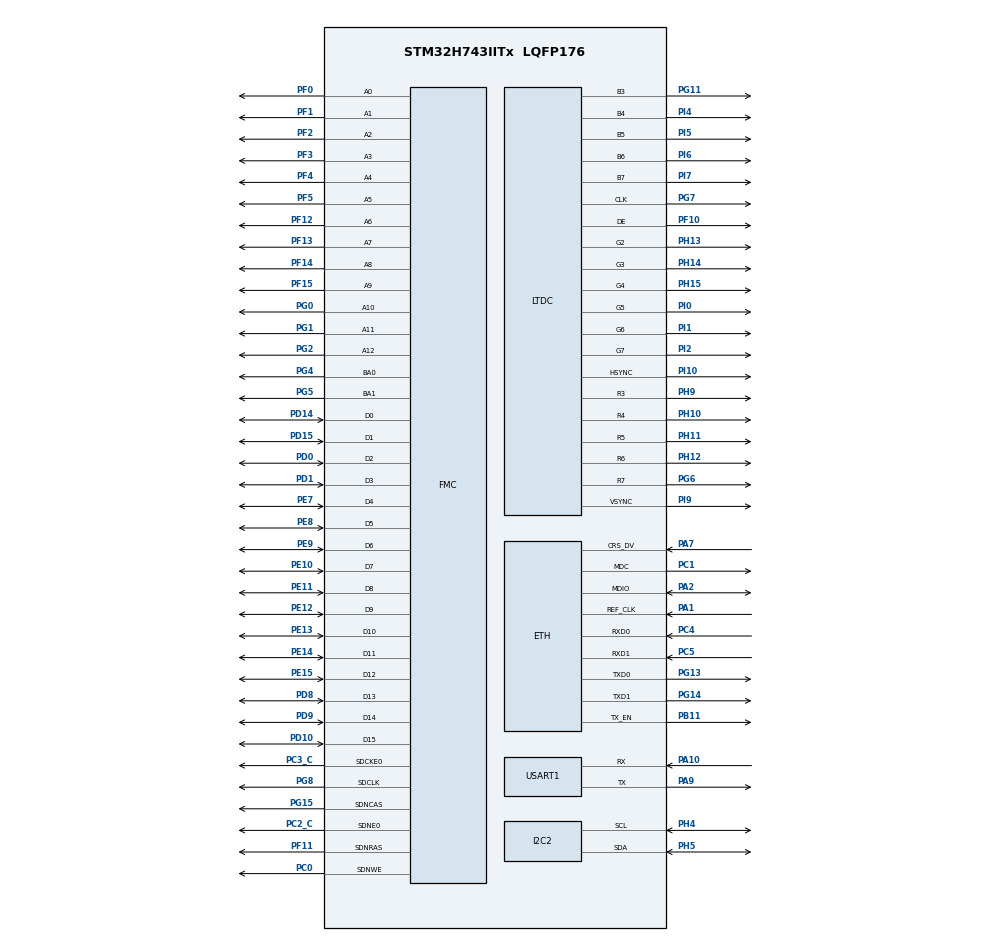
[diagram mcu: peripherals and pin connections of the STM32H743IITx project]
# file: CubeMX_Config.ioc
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CORTEX_M7.AccessPermission-Cortex_Memory_Protection_Unit_Region2_Settings=MPU_REGION_FULL_ACCESS
CORTEX_M7.AccessPermission-Cortex_Memory_Protection_Unit_Region3_Settings=MPU_REGION_FULL_ACCESS
CORTEX_M7.BaseAddress-Cortex_Memory_Protection_Unit_Region2_Settings=0x30040000
CORTEX_M7.BaseAddress-Cortex_Memory_Protection_Unit_Region3_Settings=0x30044000
CORTEX_M7.CPU_DCache=Enabled
CORTEX_M7.CPU_ICache=Enabled
CORTEX_M7.Enable-Cortex_Memory_Protection_Unit_Region2_Settings=MPU_REGION_ENABLE
CORTEX_M7.Enable-Cortex_Memory_Protection_Unit_Region3_Settings=MPU_REGION_ENABLE
CORTEX_M7.IsBufferable-Cortex_Memory_Protection_Unit_Region2_Settings=MPU_ACCESS_BUFFERABLE
CORTEX_M7.IsCacheable-Cortex_Memory_Protection_Unit_Region3_Settings=MPU_ACCESS_CACHEABLE
CORTEX_M7.MPU_Control=MPU_PRIVILEGED_DEFAULT
CORTEX_M7.Size-Cortex_Memory_Protection_Unit_Region2_Settings=MPU_REGION_SIZE_256B
CORTEX_M7.Size-Cortex_Memory_Protection_Unit_Region3_Settings=MPU_REGION_SIZE_16KB
DMA2D.ColorMode=DMA2D_OUTPUT_RGB565
DMA2D.Mode=DMA2D_R2M
ETH.MediaInterface=HAL_ETH_RMII_MODE
FMC.CASLatency1=FMC_SDRAM_CAS_LATENCY_2
FMC.ColumnBitsNumber1=FMC_SDRAM_COLUMN_BITS_NUM_9
FMC.ExitSelfRefreshDelay1=8
FMC.LoadToActiveDelay1=2
FMC.RCDDelay1=2
FMC.RPDelay1=2
FMC.ReadBurst1=FMC_SDRAM_RBURST_ENABLE
FMC.ReadPipeDelay1=FMC_SDRAM_RPIPE_DELAY_1
FMC.RowCycleDelay1=6
FMC.SDClockPeriod1=FMC_SDRAM_CLOCK_PERIOD_2
FMC.SelfRefreshTime1=6
FMC.WriteRecoveryTime1=4
I2C2.Timing=0x10C0ECFF
Mcu.Family=STM32H7
Mcu.Name=STM32H743IITx
Mcu.Package=LQFP176
NVIC.ETH_IRQn=true\:0\:0\:false\:false\:true\:true\:true
NVIC.PriorityGroup=NVIC_PRIORITYGROUP_4
NVIC.USART1_IRQn=true\:0\:0\:false\:false\:true\:true\:true
PA1.GPIO_Speed=GPIO_SPEED_FREQ_VERY_HIGH
PA1.Mode=RMII
PA1.Signal=ETH_REF_CLK
PA10.GPIO_Speed=GPIO_SPEED_FREQ_HIGH
PA10.Mode=Asynchronous
PA10.Signal=USART1_RX
PA13\ (JTMS/SWDIO).Mode=Serial_Wire
PA13\ (JTMS/SWDIO).Signal=SYS_JTMS-SWDIO
PA14\ (JTCK/SWCLK).Mode=Serial_Wire
PA14\ (JTCK/SWCLK).Signal=SYS_JTCK-SWCLK
PA2.GPIO_Speed=GPIO_SPEED_FREQ_VERY_HIGH
PA2.Mode=RMII
PA2.Signal=ETH_MDIO
PA7.GPIO_Speed=GPIO_SPEED_FREQ_VERY_HIGH
PA7.Mode=RMII
PA7.Signal=ETH_CRS_DV
PA9.GPIO_Speed=GPIO_SPEED_FREQ_HIGH
PA9.Mode=Asynchronous
PA9.Signal=USART1_TX
PB11.GPIO_Speed=GPIO_SPEED_FREQ_VERY_HIGH
PB11.Mode=RMII
PB11.Signal=ETH_TX_EN
PC0.Signal=FMC_SDNWE
PC1.Mode=RMII
PC1.Signal=ETH_MDC
PC2_C.Mode=SdramChipSelect1_1
PC2_C.Signal=FMC_SDNE0
PC3_C.Mode=SdramChipSelect1_1
PC3_C.Signal=FMC_SDCKE0
PC4.GPIO_Speed=GPIO_SPEED_FREQ_VERY_HIGH
PC4.Mode=RMII
PC4.Signal=ETH_RXD0
PC5.GPIO_Speed=GPIO_SPEED_FREQ_VERY_HIGH
PC5.Mode=RMII
PC5.Signal=ETH_RXD1
PD0.Signal=FMC_D2_DA2
PD1.Signal=FMC_D3_DA3
PD10.Signal=FMC_D15_DA15
PD14.Signal=FMC_D0_DA0
PD15.Signal=FMC_D1_DA1
PD8.Signal=FMC_D13_DA13
PD9.Signal=FMC_D14_DA14
PE0.Signal=FMC_NBL0
PE1.Signal=FMC_NBL1
PE10.Signal=FMC_D7_DA7
PE11.Signal=FMC_D8_DA8
PE12.Signal=FMC_D9_DA9
PE13.Signal=FMC_D10_DA10
PE14.Signal=FMC_D11_DA11
PE15.Signal=FMC_D12_DA12
PE7.Signal=FMC_D4_DA4
PE8.Signal=FMC_D5_DA5
PE9.Signal=FMC_D6_DA6
PF0.Signal=FMC_A0
PF1.Signal=FMC_A1
PF10.Mode=RGB565
PF10.Signal=LTDC_DE
PF11.Signal=FMC_SDNRAS
PF12.Signal=FMC_A6
PF13.Signal=FMC_A7
PF14.Signal=FMC_A8
PF15.Signal=FMC_A9
PF2.Signal=FMC_A2
PF3.Signal=FMC_A3
PF4.Signal=FMC_A4
PF5.Signal=FMC_A5
PG0.Signal=FMC_A10
PG1.Signal=FMC_A11
PG11.Mode=RGB565
PG11.Signal=LTDC_B3
PG13.GPIO_Speed=GPIO_SPEED_FREQ_VERY_HIGH
PG13.Mode=RMII
PG13.Signal=ETH_TXD0
PG14.GPIO_Speed=GPIO_SPEED_FREQ_VERY_HIGH
PG14.Mode=RMII
PG14.Signal=ETH_TXD1
PG15.Signal=FMC_SDNCAS
PG2.Signal=FMC_A12
PG4.Signal=FMC_A14_BA0
PG5.Signal=FMC_A15_BA1
PG6.Mode=RGB565
PG6.Signal=LTDC_R7
PG7.Mode=RGB565
PG7.Signal=LTDC_CLK
PG8.Signal=FMC_SDCLK
PH0-OSC_IN\ (PH0).Mode=HSE-External-Oscillator
PH0-OSC_IN\ (PH0).Signal=RCC_OSC_IN
PH1-OSC_OUT\ (PH1).Mode=HSE-External-Oscillator
PH1-OSC_OUT\ (PH1).Signal=RCC_OSC_OUT
PH10.Mode=RGB565
PH10.Signal=LTDC_R4
PH11.Mode=RGB565
PH11.Signal=LTDC_R5
PH12.Mode=RGB565
PH12.Signal=LTDC_R6
PH13.Mode=RGB565
PH13.Signal=LTDC_G2
PH14.Mode=RGB565
PH14.Signal=LTDC_G3
PH15.Mode=RGB565
PH15.Signal=LTDC_G4
PH4.GPIO_Speed=GPIO_SPEED_FREQ_HIGH
PH4.Mode=I2C
PH4.Signal=I2C2_SCL
PH5.GPIO_Speed=GPIO_SPEED_FREQ_HIGH
PH5.Mode=I2C
PH5.Signal=I2C2_SDA
PH9.Mode=RGB565
PH9.Signal=LTDC_R3
PI0.Mode=RGB565
PI0.Signal=LTDC_G5
PI1.Mode=RGB565
PI1.Signal=LTDC_G6
PI10.Mode=RGB565
PI10.Signal=LTDC_HSYNC
PI2.Mode=RGB565
PI2.Signal=LTDC_G7
PI4.Mode=RGB565
PI4.Signal=LTDC_B4
PI5.Mode=RGB565
PI5.Signal=LTDC_B5
PI6.Mode=RGB565
PI6.Signal=LTDC_B6
PI7.Mode=RGB565
PI7.Signal=LTDC_B7
PI9.Mode=RGB565
PI9.Signal=LTDC_VSYNC
ProjectManager.HeapSize=0x200
ProjectManager.StackSize=0x400
ProjectManager.TargetToolchain=MDK-ARM V5
RCC.ADCFreq_Value=50390625
RCC.APB1Freq_Value=100000000
RCC.APB2Freq_Value=100000000
RCC.APB3Freq_Value=100000000
RCC.APB4Freq_Value=100000000
RCC.CortexFreq_Value=400000000
RCC.D1PPRE=RCC_APB3_DIV2
RCC.D2PPRE1=RCC_APB1_DIV2
RCC.D2PPRE2=RCC_APB2_DIV2
RCC.D3PPRE=RCC_APB4_DIV2
RCC.DIVM1=5
RCC.DIVM3=5
RCC.DIVN1=160
RCC.DIVN3=160
RCC.DIVR3=88
RCC.HCLKFreq_Value=200000000
RCC.HPRE=RCC_HCLK_DIV2
RCC.HSE_VALUE=25000000
RCC.PLLSourceVirtual=RCC_PLLSOURCE_HSE
RCC.SYSCLKFreq_VALUE=400000000
RCC.SYSCLKSource=RCC_SYSCLKSOURCE_PLLCLK
RCC.USBFreq_Value=400000000
SH.FMC_A0.0=FMC_A0,13b-sda1
SH.FMC_A1.0=FMC_A1,13b-sda1
SH.FMC_A10.0=FMC_A10,13b-sda1
SH.FMC_A11.0=FMC_A11,13b-sda1
SH.FMC_A12.0=FMC_A12,13b-sda1
SH.FMC_A14_BA0.0=FMC_BA0,FourSdramBanks1
SH.FMC_A15_BA1.0=FMC_BA1,FourSdramBanks1
SH.FMC_A2.0=FMC_A2,13b-sda1
SH.FMC_A3.0=FMC_A3,13b-sda1
SH.FMC_A4.0=FMC_A4,13b-sda1
SH.FMC_A5.0=FMC_A5,13b-sda1
SH.FMC_A6.0=FMC_A6,13b-sda1
SH.FMC_A7.0=FMC_A7,13b-sda1
SH.FMC_A8.0=FMC_A8,13b-sda1
SH.FMC_A9.0=FMC_A9,13b-sda1
SH.FMC_D0_DA0.0=FMC_D0,sd-16b-d1
SH.FMC_D10_DA10.0=FMC_D10,sd-16b-d1
SH.FMC_D11_DA11.0=FMC_D11,sd-16b-d1
SH.FMC_D12_DA12.0=FMC_D12,sd-16b-d1
SH.FMC_D13_DA13.0=FMC_D13,sd-16b-d1
SH.FMC_D14_DA14.0=FMC_D14,sd-16b-d1
SH.FMC_D15_DA15.0=FMC_D15,sd-16b-d1
SH.FMC_D1_DA1.0=FMC_D1,sd-16b-d1
SH.FMC_D2_DA2.0=FMC_D2,sd-16b-d1
SH.FMC_D3_DA3.0=FMC_D3,sd-16b-d1
SH.FMC_D4_DA4.0=FMC_D4,sd-16b-d1
SH.FMC_D5_DA5.0=FMC_D5,sd-16b-d1
SH.FMC_D6_DA6.0=FMC_D6,sd-16b-d1
SH.FMC_D7_DA7.0=FMC_D7,sd-16b-d1
SH.FMC_D8_DA8.0=FMC_D8,sd-16b-d1
SH.FMC_D9_DA9.0=FMC_D9,sd-16b-d1
SH.FMC_NBL0.0=FMC_NBL0
SH.FMC_NBL1.0=FMC_NBL1
SH.FMC_SDCLK.0=FMC_SDCLK,13b-sda1
SH.FMC_SDNCAS.0=FMC_SDNCAS,13b-sda1
SH.FMC_SDNRAS.0=FMC_SDNRAS,13b-sda1
SH.FMC_SDNWE.0=FMC_SDNWE,13b-sda1
USART1.VirtualMode-Asynchronous=VM_ASYNC
VP_DMA2D_VS_DMA2D.Mode=DMA2D_Activate
board=custom

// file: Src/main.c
/* USER CODE BEGIN Header */
/**
  ******************************************************************************
  * @file           : main.c
  * @brief          : Main program body
  ******************************************************************************
  ** This notice applies to any and all portions of this file
  * that are not between comment pairs USER CODE BEGIN and
  * USER CODE END. Other portions of this file, whether
  * inserted by the user or by software development tools
  * are owned by their respective copyright owners.
  *
  * COPYRIGHT(c) 2019 STMicroelectronics
  *
  * Redistribution and use in source and binary forms, with or without modification,
  * are permitted provided that the following conditions are met:
  *   1. Redistributions of source code must retain the above copyright notice,
  *      this list of conditions and the following disclaimer.
  *   2. Redistributions in binary form must reproduce the above copyright notice,
  *      this list of conditions and the following disclaimer in the documentation
  *      and/or other materials provided with the distribution.
  *   3. Neither the name of STMicroelectronics nor the names of its contributors
  *      may be used to endorse or promote products derived from this software
  *      without specific prior written permission.
  *
  * THIS SOFTWARE IS PROVIDED BY THE COPYRIGHT HOLDERS AND CONTRIBUTORS "AS IS"
  * AND ANY EXPRESS OR IMPLIED WARRANTIES, INCLUDING, BUT NOT LIMITED TO, THE
  * IMPLIED WARRANTIES OF MERCHANTABILITY AND FITNESS FOR A PARTICULAR PURPOSE ARE
  * DISCLAIMED. IN NO EVENT SHALL THE COPYRIGHT HOLDER OR CONTRIBUTORS BE LIABLE
  * FOR ANY DIRECT, INDIRECT, INCIDENTAL, SPECIAL, EXEMPLARY, OR CONSEQUENTIAL
  * DAMAGES (INCLUDING, BUT NOT LIMITED TO, PROCUREMENT OF SUBSTITUTE GOODS OR
  * SERVICES; LOSS OF USE, DATA, OR PROFITS; OR BUSINESS INTERRUPTION) HOWEVER
  * CAUSED AND ON ANY THEORY OF LIABILITY, WHETHER IN CONTRACT, STRICT LIABILITY,
  * OR TORT (INCLUDING NEGLIGENCE OR OTHERWISE) ARISING IN ANY WAY OUT OF THE USE
  * OF THIS SOFTWARE, EVEN IF ADVISED OF THE POSSIBILITY OF SUCH DAMAGE.
  *
  ******************************************************************************
  */
/* USER CODE END Header */

#include "main.h"

/* USER CODE BEGIN Includes */
#include "pcf8574.h"
#include "stdio.h"
/* USER CODE END Includes */

DMA2D_HandleTypeDef hdma2d;

ETH_HandleTypeDef heth;

I2C_HandleTypeDef hi2c2;

LTDC_HandleTypeDef hltdc;

UART_HandleTypeDef huart1;

SDRAM_HandleTypeDef hsdram1;

void SystemClock_Config(void);
static void MPU_Config(void);
static void MX_GPIO_Init(void);
static void MX_USART1_UART_Init(void);
static void MX_FMC_Init(void);
static void MX_DMA2D_Init(void);
static void MX_LTDC_Init(void);
static void MX_I2C2_Init(void);
static void MX_ETH_Init(void);

/* USER CODE BEGIN 0 */
int fputc(int ch, FILE *f)
{
    HAL_UART_Transmit(&huart1, (uint8_t *)&ch, 1, 1000);
    return ch;
}
/* USER CODE END 0 */

int main(void)
{

  /* MPU Configuration--------------------------------------------------------*/
  MPU_Config();

  /* Enable I-Cache---------------------------------------------------------*/
  SCB_EnableICache();

  /* Enable D-Cache---------------------------------------------------------*/
  SCB_EnableDCache();

  /* MCU Configuration--------------------------------------------------------*/

  /* Reset of all peripherals, Initializes the Flash interface and the Systick. */
  HAL_Init();

  /* USER CODE BEGIN Init */
    __HAL_RCC_D2SRAM3_CLK_ENABLE();
  /* USER CODE END Init */

  /* Configure the system clock */
  SystemClock_Config();

  /* Initialize all configured peripherals */
  MX_GPIO_Init();
  MX_USART1_UART_Init();
  MX_FMC_Init();
  MX_DMA2D_Init();
  MX_LTDC_Init();
  MX_I2C2_Init();
  MX_ETH_Init();
  /* USER CODE BEGIN 2 */
  MX_LWIP_Init();
    printf("开始\r\n");
  /* USER CODE END 2 */

  /* Infinite loop */
  while (1)
  {

    /* USER CODE BEGIN 3 */
      MX_LWIP_Process();
  }
  /* USER CODE END 3 */
}

void SystemClock_Config(void)
{
  RCC_OscInitTypeDef RCC_OscInitStruct = {0};
  RCC_ClkInitTypeDef RCC_ClkInitStruct = {0};
  RCC_PeriphCLKInitTypeDef PeriphClkInitStruct = {0};

  /**Supply configuration update enable
  */
  MODIFY_REG(PWR->CR3, PWR_CR3_SCUEN, 0);
  /**Configure the main internal regulator output voltage
  */
  __HAL_PWR_VOLTAGESCALING_CONFIG(PWR_REGULATOR_VOLTAGE_SCALE1);

  while ((PWR->D3CR & (PWR_D3CR_VOSRDY)) != PWR_D3CR_VOSRDY)
  {

  }
  /**Macro to configure the PLL clock source
  */
  __HAL_RCC_PLL_PLLSOURCE_CONFIG(RCC_PLLSOURCE_HSE);
  /**Initializes the CPU, AHB and APB busses clocks
  */
  RCC_OscInitStruct.OscillatorType = RCC_OSCILLATORTYPE_HSE;
  RCC_OscInitStruct.HSEState = RCC_HSE_ON;
  RCC_OscInitStruct.PLL.PLLState = RCC_PLL_ON;
  RCC_OscInitStruct.PLL.PLLSource = RCC_PLLSOURCE_HSE;
  RCC_OscInitStruct.PLL.PLLM = 5;
  RCC_OscInitStruct.PLL.PLLN = 160;
  RCC_OscInitStruct.PLL.PLLP = 2;
  RCC_OscInitStruct.PLL.PLLQ = 2;
  RCC_OscInitStruct.PLL.PLLR = 2;
  RCC_OscInitStruct.PLL.PLLRGE = RCC_PLL1VCIRANGE_2;
  RCC_OscInitStruct.PLL.PLLVCOSEL = RCC_PLL1VCOWIDE;
  RCC_OscInitStruct.PLL.PLLFRACN = 0;
  if (HAL_RCC_OscConfig(&RCC_OscInitStruct) != HAL_OK)
  {
    Error_Handler();
  }
  /**Initializes the CPU, AHB and APB busses clocks
  */
  RCC_ClkInitStruct.ClockType = RCC_CLOCKTYPE_HCLK|RCC_CLOCKTYPE_SYSCLK
                              |RCC_CLOCKTYPE_PCLK1|RCC_CLOCKTYPE_PCLK2
                              |RCC_CLOCKTYPE_D3PCLK1|RCC_CLOCKTYPE_D1PCLK1;
  RCC_ClkInitStruct.SYSCLKSource = RCC_SYSCLKSOURCE_PLLCLK;
  RCC_ClkInitStruct.SYSCLKDivider = RCC_SYSCLK_DIV1;
  RCC_ClkInitStruct.AHBCLKDivider = RCC_HCLK_DIV2;
  RCC_ClkInitStruct.APB3CLKDivider = RCC_APB3_DIV2;
  RCC_ClkInitStruct.APB1CLKDivider = RCC_APB1_DIV2;
  RCC_ClkInitStruct.APB2CLKDivider = RCC_APB2_DIV2;
  RCC_ClkInitStruct.APB4CLKDivider = RCC_APB4_DIV2;

  if (HAL_RCC_ClockConfig(&RCC_ClkInitStruct, FLASH_LATENCY_2) != HAL_OK)
  {
    Error_Handler();
  }
  PeriphClkInitStruct.PeriphClockSelection = RCC_PERIPHCLK_LTDC|RCC_PERIPHCLK_USART1
                              |RCC_PERIPHCLK_I2C2|RCC_PERIPHCLK_FMC;
  PeriphClkInitStruct.PLL3.PLL3M = 5;
  PeriphClkInitStruct.PLL3.PLL3N = 160;
  PeriphClkInitStruct.PLL3.PLL3P = 2;
  PeriphClkInitStruct.PLL3.PLL3Q = 2;
  PeriphClkInitStruct.PLL3.PLL3R = 88;
  PeriphClkInitStruct.PLL3.PLL3RGE = RCC_PLL3VCIRANGE_2;
  PeriphClkInitStruct.PLL3.PLL3VCOSEL = RCC_PLL3VCOWIDE;
  PeriphClkInitStruct.PLL3.PLL3FRACN = 0;
  PeriphClkInitStruct.FmcClockSelection = RCC_FMCCLKSOURCE_D1HCLK;
  PeriphClkInitStruct.Usart16ClockSelection = RCC_USART16CLKSOURCE_D2PCLK2;
  PeriphClkInitStruct.I2c123ClockSelection = RCC_I2C123CLKSOURCE_D2PCLK1;
  if (HAL_RCCEx_PeriphCLKConfig(&PeriphClkInitStruct) != HAL_OK)
  {
    Error_Handler();
  }
}

static void MX_DMA2D_Init(void)
{

  hdma2d.Instance = DMA2D;
  hdma2d.Init.Mode = DMA2D_R2M;
  hdma2d.Init.ColorMode = DMA2D_OUTPUT_RGB565;
  hdma2d.Init.OutputOffset = 0;
  if (HAL_DMA2D_Init(&hdma2d) != HAL_OK)
  {
    Error_Handler();
  }

}

static void MX_ETH_Init(void)
{

   uint8_t MACAddr[6] ;

  heth.Instance = ETH;
  MACAddr[0] = 0x00;
  MACAddr[1] = 0x80;
  MACAddr[2] = 0xE1;
  MACAddr[3] = 0x00;
  MACAddr[4] = 0x00;
  MACAddr[5] = 0x00;
  heth.Init.MACAddr = &MACAddr[0];
  heth.Init.MediaInterface = HAL_ETH_RMII_MODE;
  heth.Init.TxDesc = DMATxDscrTab;
  heth.Init.RxDesc = DMARxDscrTab;
  heth.Init.RxBuffLen = 1524;

  if (HAL_ETH_Init(&heth) != HAL_OK)
  {
    Error_Handler();
  }

  memset(&TxConfig, 0 , sizeof(ETH_TxPacketConfig));
  TxConfig.Attributes = ETH_TX_PACKETS_FEATURES_CSUM | ETH_TX_PACKETS_FEATURES_CRCPAD;
  TxConfig.ChecksumCtrl = ETH_CHECKSUM_IPHDR_PAYLOAD_INSERT_PHDR_CALC;
  TxConfig.CRCPadCtrl = ETH_CRC_PAD_INSERT;

}

static void MX_I2C2_Init(void)
{

  hi2c2.Instance = I2C2;
  hi2c2.Init.Timing = 0x10C0ECFF;
  hi2c2.Init.OwnAddress1 = 0;
  hi2c2.Init.AddressingMode = I2C_ADDRESSINGMODE_7BIT;
  hi2c2.Init.DualAddressMode = I2C_DUALADDRESS_DISABLE;
  hi2c2.Init.OwnAddress2 = 0;
  hi2c2.Init.OwnAddress2Masks = I2C_OA2_NOMASK;
  hi2c2.Init.GeneralCallMode = I2C_GENERALCALL_DISABLE;
  hi2c2.Init.NoStretchMode = I2C_NOSTRETCH_DISABLE;
  if (HAL_I2C_Init(&hi2c2) != HAL_OK)
  {
    Error_Handler();
  }
  /**Configure Analogue filter
  */
  if (HAL_I2CEx_ConfigAnalogFilter(&hi2c2, I2C_ANALOGFILTER_ENABLE) != HAL_OK)
  {
    Error_Handler();
  }
  /**Configure Digital filter
  */
  if (HAL_I2CEx_ConfigDigitalFilter(&hi2c2, 0) != HAL_OK)
  {
    Error_Handler();
  }
  /* USER CODE BEGIN I2C2_Init 2 */
    PCF8574_Init();
    PCF8574_WriteBit(BEEP_IO, 0);
    HAL_Delay(10);
    PCF8574_WriteBit(BEEP_IO, 1);

    PCF8574_WriteBit(ETH_RESET_IO, 1);
    HAL_Delay(100);
    PCF8574_WriteBit(ETH_RESET_IO, 0);
    HAL_Delay(100);
  /* USER CODE END I2C2_Init 2 */

}

static void MX_LTDC_Init(void)
{

  LTDC_LayerCfgTypeDef pLayerCfg = {0};
  LTDC_LayerCfgTypeDef pLayerCfg1 = {0};

  hltdc.Instance = LTDC;
  hltdc.Init.HSPolarity = LTDC_HSPOLARITY_AL;
  hltdc.Init.VSPolarity = LTDC_VSPOLARITY_AL;
  hltdc.Init.DEPolarity = LTDC_DEPOLARITY_AL;
  hltdc.Init.PCPolarity = LTDC_PCPOLARITY_IPC;
  hltdc.Init.HorizontalSync = 7;
  hltdc.Init.VerticalSync = 3;
  hltdc.Init.AccumulatedHBP = 14;
  hltdc.Init.AccumulatedVBP = 5;
  hltdc.Init.AccumulatedActiveW = 654;
  hltdc.Init.AccumulatedActiveH = 485;
  hltdc.Init.TotalWidth = 660;
  hltdc.Init.TotalHeigh = 487;
  hltdc.Init.Backcolor.Blue = 0;
  hltdc.Init.Backcolor.Green = 0;
  hltdc.Init.Backcolor.Red = 0;
  if (HAL_LTDC_Init(&hltdc) != HAL_OK)
  {
    Error_Handler();
  }
  pLayerCfg.WindowX0 = 0;
  pLayerCfg.WindowX1 = 0;
  pLayerCfg.WindowY0 = 0;
  pLayerCfg.WindowY1 = 0;
  pLayerCfg.PixelFormat = LTDC_PIXEL_FORMAT_ARGB8888;
  pLayerCfg.Alpha = 0;
  pLayerCfg.Alpha0 = 0;
  pLayerCfg.BlendingFactor1 = LTDC_BLENDING_FACTOR1_CA;
  pLayerCfg.BlendingFactor2 = LTDC_BLENDING_FACTOR2_CA;
  pLayerCfg.FBStartAdress = 0;
  pLayerCfg.ImageWidth = 0;
  pLayerCfg.ImageHeight = 0;
  pLayerCfg.Backcolor.Blue = 0;
  pLayerCfg.Backcolor.Green = 0;
  pLayerCfg.Backcolor.Red = 0;
  if (HAL_LTDC_ConfigLayer(&hltdc, &pLayerCfg, 0) != HAL_OK)
  {
    Error_Handler();
  }
  pLayerCfg1.WindowX0 = 0;
  pLayerCfg1.WindowX1 = 0;
  pLayerCfg1.WindowY0 = 0;
  pLayerCfg1.WindowY1 = 0;
  pLayerCfg1.PixelFormat = LTDC_PIXEL_FORMAT_ARGB8888;
  pLayerCfg1.Alpha = 0;
  pLayerCfg1.Alpha0 = 0;
  pLayerCfg1.BlendingFactor1 = LTDC_BLENDING_FACTOR1_CA;
  pLayerCfg1.BlendingFactor2 = LTDC_BLENDING_FACTOR2_CA;
  pLayerCfg1.FBStartAdress = 0;
  pLayerCfg1.ImageWidth = 0;
  pLayerCfg1.ImageHeight = 0;
  pLayerCfg1.Backcolor.Blue = 0;
  pLayerCfg1.Backcolor.Green = 0;
  pLayerCfg1.Backcolor.Red = 0;
  if (HAL_LTDC_ConfigLayer(&hltdc, &pLayerCfg1, 1) != HAL_OK)
  {
    Error_Handler();
  }

}

static void MX_USART1_UART_Init(void)
{

  huart1.Instance = USART1;
  huart1.Init.BaudRate = 115200;
  huart1.Init.WordLength = UART_WORDLENGTH_8B;
  huart1.Init.StopBits = UART_STOPBITS_1;
  huart1.Init.Parity = UART_PARITY_NONE;
  huart1.Init.Mode = UART_MODE_TX_RX;
  huart1.Init.HwFlowCtl = UART_HWCONTROL_NONE;
  huart1.Init.OverSampling = UART_OVERSAMPLING_16;
  huart1.Init.OneBitSampling = UART_ONE_BIT_SAMPLE_DISABLE;
  huart1.Init.Prescaler = UART_PRESCALER_DIV1;
  huart1.Init.FIFOMode = UART_FIFOMODE_DISABLE;
  huart1.Init.TXFIFOThreshold = UART_TXFIFO_THRESHOLD_1_8;
  huart1.Init.RXFIFOThreshold = UART_RXFIFO_THRESHOLD_1_8;
  huart1.AdvancedInit.AdvFeatureInit = UART_ADVFEATURE_NO_INIT;
  if (HAL_UART_Init(&huart1) != HAL_OK)
  {
    Error_Handler();
  }

}

/* FMC initialization function */
static void MX_FMC_Init(void)
{
  FMC_SDRAM_TimingTypeDef SdramTiming;

  /** Perform the SDRAM1 memory initialization sequence
  */
  hsdram1.Instance = FMC_SDRAM_DEVICE;
  /* hsdram1.Init */
  hsdram1.Init.SDBank = FMC_SDRAM_BANK1;
  hsdram1.Init.ColumnBitsNumber = FMC_SDRAM_COLUMN_BITS_NUM_9;
  hsdram1.Init.RowBitsNumber = FMC_SDRAM_ROW_BITS_NUM_13;
  hsdram1.Init.MemoryDataWidth = FMC_SDRAM_MEM_BUS_WIDTH_16;
  hsdram1.Init.InternalBankNumber = FMC_SDRAM_INTERN_BANKS_NUM_4;
  hsdram1.Init.CASLatency = FMC_SDRAM_CAS_LATENCY_2;
  hsdram1.Init.WriteProtection = FMC_SDRAM_WRITE_PROTECTION_DISABLE;
  hsdram1.Init.SDClockPeriod = FMC_SDRAM_CLOCK_PERIOD_2;
  hsdram1.Init.ReadBurst = FMC_SDRAM_RBURST_ENABLE;
  hsdram1.Init.ReadPipeDelay = FMC_SDRAM_RPIPE_DELAY_1;
  /* SdramTiming */
  SdramTiming.LoadToActiveDelay = 2;
  SdramTiming.ExitSelfRefreshDelay = 8;
  SdramTiming.SelfRefreshTime = 6;
  SdramTiming.RowCycleDelay = 6;
  SdramTiming.WriteRecoveryTime = 4;
  SdramTiming.RPDelay = 2;
  SdramTiming.RCDDelay = 2;

  if (HAL_SDRAM_Init(&hsdram1, &SdramTiming) != HAL_OK)
  {
    Error_Handler( );
  }

}

static void MX_GPIO_Init(void)
{

  /* GPIO Ports Clock Enable */
  __HAL_RCC_GPIOI_CLK_ENABLE();
  __HAL_RCC_GPIOF_CLK_ENABLE();
  __HAL_RCC_GPIOH_CLK_ENABLE();
  __HAL_RCC_GPIOC_CLK_ENABLE();
  __HAL_RCC_GPIOA_CLK_ENABLE();
  __HAL_RCC_GPIOG_CLK_ENABLE();
  __HAL_RCC_GPIOE_CLK_ENABLE();
  __HAL_RCC_GPIOB_CLK_ENABLE();
  __HAL_RCC_GPIOD_CLK_ENABLE();

}

/* MPU Configuration */

void MPU_Config(void)
{
  MPU_Region_InitTypeDef MPU_InitStruct = {0};

  /* Disables the MPU */
  HAL_MPU_Disable();
  /**Initializes and configures the Region and the memory to be protected
  */
  MPU_InitStruct.Enable = MPU_REGION_ENABLE;
  MPU_InitStruct.Number = MPU_REGION_NUMBER2;
  MPU_InitStruct.BaseAddress = 0x30040000;
  MPU_InitStruct.Size = MPU_REGION_SIZE_256B;
  MPU_InitStruct.SubRegionDisable = 0x0;
  MPU_InitStruct.TypeExtField = MPU_TEX_LEVEL0;
  MPU_InitStruct.AccessPermission = MPU_REGION_FULL_ACCESS;
  MPU_InitStruct.DisableExec = MPU_INSTRUCTION_ACCESS_ENABLE;
  MPU_InitStruct.IsShareable = MPU_ACCESS_NOT_SHAREABLE;
  MPU_InitStruct.IsCacheable = MPU_ACCESS_NOT_CACHEABLE;
  MPU_InitStruct.IsBufferable = MPU_ACCESS_BUFFERABLE;

  HAL_MPU_ConfigRegion(&MPU_InitStruct);
  /**Initializes and configures the Region and the memory to be protected
  */
  MPU_InitStruct.Enable = MPU_REGION_ENABLE;
  MPU_InitStruct.Number = MPU_REGION_NUMBER3;
  MPU_InitStruct.BaseAddress = 0x30044000;
  MPU_InitStruct.Size = MPU_REGION_SIZE_16KB;
  MPU_InitStruct.SubRegionDisable = 0x0;
  MPU_InitStruct.TypeExtField = MPU_TEX_LEVEL0;
  MPU_InitStruct.AccessPermission = MPU_REGION_FULL_ACCESS;
  MPU_InitStruct.DisableExec = MPU_INSTRUCTION_ACCESS_ENABLE;
  MPU_InitStruct.IsShareable = MPU_ACCESS_NOT_SHAREABLE;
  MPU_InitStruct.IsCacheable = MPU_ACCESS_CACHEABLE;
  MPU_InitStruct.IsBufferable = MPU_ACCESS_NOT_BUFFERABLE;

  HAL_MPU_ConfigRegion(&MPU_InitStruct);
  /* Enables the MPU */
  HAL_MPU_Enable(MPU_PRIVILEGED_DEFAULT);

}

void Error_Handler(void)
{
}

/************************ (C) COPYRIGHT STMicroelectronics *****END OF FILE****/
